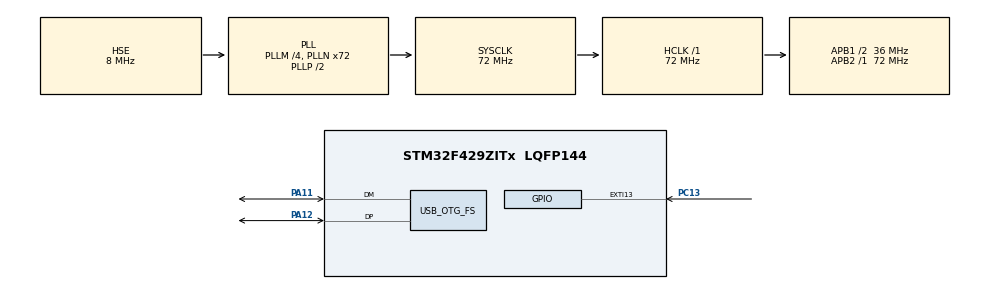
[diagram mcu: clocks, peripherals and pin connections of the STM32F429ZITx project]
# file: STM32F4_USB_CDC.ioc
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Mcu.Family=STM32F4
Mcu.Name=STM32F429ZITx
Mcu.Package=LQFP144
NVIC.EXTI15_10_IRQn=true\:0\:0\:false\:false\:true\:true\:true\:true
NVIC.OTG_FS_IRQn=true\:0\:0\:false\:false\:true\:true\:true\:true
NVIC.PriorityGroup=NVIC_PRIORITYGROUP_4
PA11.Mode=Device_Only
PA11.Signal=USB_OTG_FS_DM
PA12.Mode=Device_Only
PA12.Signal=USB_OTG_FS_DP
PC13.GPIO_ModeDefaultEXTI=GPIO_MODE_IT_RISING
PC13.Signal=GPXTI13
PH0/OSC_IN.Mode=HSE-External-Clock-Source
PH0/OSC_IN.Signal=RCC_OSC_IN
PH1/OSC_OUT.Mode=HSE-External-Clock-Source
PH1/OSC_OUT.Signal=RCC_OSC_OUT
ProjectManager.HeapSize=0x400
ProjectManager.StackSize=0x600
ProjectManager.TargetToolchain=STM32CubeIDE
RCC.48MHZClocksFreq_Value=48000000
RCC.AHBFreq_Value=72000000
RCC.APB1CLKDivider=RCC_HCLK_DIV2
RCC.APB1Freq_Value=36000000
RCC.APB1TimFreq_Value=72000000
RCC.APB2Freq_Value=72000000
RCC.APB2TimFreq_Value=72000000
RCC.CortexFreq_Value=72000000
RCC.HCLKFreq_Value=72000000
RCC.HSE_VALUE=8000000
RCC.HSI_VALUE=16000000
RCC.LSE_VALUE=32768
RCC.PLLM=4
RCC.PLLN=72
RCC.PLLQ=3
RCC.SYSCLKFreq_VALUE=72000000
RCC.SYSCLKSource=RCC_SYSCLKSOURCE_PLLCLK
RCC.VCOOutputFreq_Value=144000000
USB_DEVICE.CLASS_NAME_FS=HID
USB_DEVICE.VirtualMode-HID_FS=Hid
USB_DEVICE.VirtualModeFS=Hid_FS
USB_OTG_FS.VirtualMode=Device_Only
VP_USB_DEVICE_VS_USB_DEVICE_HID_FS.Mode=HID_FS
board=custom

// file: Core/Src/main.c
/* USER CODE BEGIN Header */
/**
  ******************************************************************************
  * @file           : main.c
  * @brief          : Main program body
  ******************************************************************************
  * @attention
  *
  * Copyright (c) 2026 STMicroelectronics.
  * All rights reserved.
  *
  * This software is licensed under terms that can be found in the LICENSE file
  * in the root directory of this software component.
  * If no LICENSE file comes with this software, it is provided AS-IS.
  *
  ******************************************************************************
  */
/* USER CODE END Header */
#include "main.h"
#include "usb_device.h"

/* USER CODE BEGIN Includes */
#include "usbd_hid.h"
/* USER CODE END Includes */

/* USER CODE BEGIN PV */
extern USBD_HandleTypeDef hUsbDeviceFS;
uint8_t buffer[4];
/* USER CODE END PV */

void SystemClock_Config(void);
static void MX_GPIO_Init(void);

int main(void)
{

  /* MCU Configuration--------------------------------------------------------*/

  /* Reset of all peripherals, Initializes the Flash interface and the Systick. */
  HAL_Init();

  /* Configure the system clock */
  SystemClock_Config();

  /* Initialize all configured peripherals */
  MX_GPIO_Init();
  MX_USB_DEVICE_Init();

  /* Infinite loop */
  while (1)
  {

  }
}

void SystemClock_Config(void)
{
  RCC_OscInitTypeDef RCC_OscInitStruct = {0};
  RCC_ClkInitTypeDef RCC_ClkInitStruct = {0};

  /** Configure the main internal regulator output voltage
  */
  __HAL_RCC_PWR_CLK_ENABLE();
  __HAL_PWR_VOLTAGESCALING_CONFIG(PWR_REGULATOR_VOLTAGE_SCALE3);

  /** Initializes the RCC Oscillators according to the specified parameters
  * in the RCC_OscInitTypeDef structure.
  */
  RCC_OscInitStruct.OscillatorType = RCC_OSCILLATORTYPE_HSE;
  RCC_OscInitStruct.HSEState = RCC_HSE_BYPASS;
  RCC_OscInitStruct.PLL.PLLState = RCC_PLL_ON;
  RCC_OscInitStruct.PLL.PLLSource = RCC_PLLSOURCE_HSE;
  RCC_OscInitStruct.PLL.PLLM = 4;
  RCC_OscInitStruct.PLL.PLLN = 72;
  RCC_OscInitStruct.PLL.PLLP = RCC_PLLP_DIV2;
  RCC_OscInitStruct.PLL.PLLQ = 3;
  if (HAL_RCC_OscConfig(&RCC_OscInitStruct) != HAL_OK)
  {
    Error_Handler();
  }

  /** Initializes the CPU, AHB and APB buses clocks
  */
  RCC_ClkInitStruct.ClockType = RCC_CLOCKTYPE_HCLK|RCC_CLOCKTYPE_SYSCLK
                              |RCC_CLOCKTYPE_PCLK1|RCC_CLOCKTYPE_PCLK2;
  RCC_ClkInitStruct.SYSCLKSource = RCC_SYSCLKSOURCE_PLLCLK;
  RCC_ClkInitStruct.AHBCLKDivider = RCC_SYSCLK_DIV1;
  RCC_ClkInitStruct.APB1CLKDivider = RCC_HCLK_DIV2;
  RCC_ClkInitStruct.APB2CLKDivider = RCC_HCLK_DIV1;

  if (HAL_RCC_ClockConfig(&RCC_ClkInitStruct, FLASH_LATENCY_2) != HAL_OK)
  {
    Error_Handler();
  }
}

static void MX_GPIO_Init(void)
{
  GPIO_InitTypeDef GPIO_InitStruct = {0};

  /* GPIO Ports Clock Enable */
  __HAL_RCC_GPIOC_CLK_ENABLE();
  __HAL_RCC_GPIOH_CLK_ENABLE();
  __HAL_RCC_GPIOA_CLK_ENABLE();

  /*Configure GPIO pin : PC13 */
  GPIO_InitStruct.Pin = GPIO_PIN_13;
  GPIO_InitStruct.Mode = GPIO_MODE_IT_RISING;
  GPIO_InitStruct.Pull = GPIO_NOPULL;
  HAL_GPIO_Init(GPIOC, &GPIO_InitStruct);

  /* EXTI interrupt init*/
  HAL_NVIC_SetPriority(EXTI15_10_IRQn, 0, 0);
  HAL_NVIC_EnableIRQ(EXTI15_10_IRQn);

}

/* USER CODE BEGIN 4 */
void HAL_GPIO_EXTI_Callback(uint16_t GPIO_Pin)
{
	buffer[0] = 0; // Mouse buttons
	buffer[1] = 100; // X axis mouse movement
	buffer[2] = 100; // Y axis mouse movement
	buffer[3] = 0; // Mouse Wheel

	USBD_HID_SendReport(&hUsbDeviceFS, buffer, 4);
}
/* USER CODE END 4 */

void Error_Handler(void)
{
  __disable_irq();
  while (1)
  {
  }
}
